# STM32L552xx register map
File version: 1.0
Registers are 32-bit, read-write, reset 0x0 unless marked. A register's access mark holds for its fields unless they carry their own. Offsets are from the block's base; [hi:lo] are bit positions; {n}, {i} and the like mark numbered series.

## SPI2 — Serial Peripheral Interface
Base 0x40003800
Same registers: SPI3 0x40003C00, SPI1 0x40013000, SPI2_S 0x50003800, SPI3_S 0x50003C00, SPI1_S 0x50013000
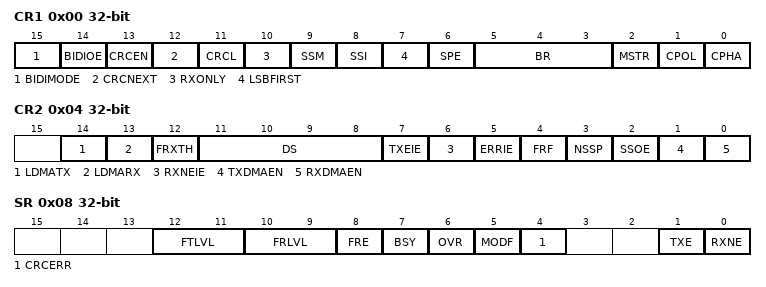
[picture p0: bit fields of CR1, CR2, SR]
0x00 CR1 — SPI Control register 1
  [15] BIDIMODE — Bidirectional data mode enable
  [14] BIDIOE — Output enable in bidirectional mode
  [13] CRCEN — Hardware CRC calculation enable
  [12] CRCNEXT — Transmit CRC next
  [11] CRCL — CRC Length
    0=CRC_8BIT (8-bit CRC length); 1=CRC_16BIT (16-bit CRC length)
  [10] RXONLY — Receive only
  [9] SSM — Software slave management
  [8] SSI — Internal slave select
  [7] LSBFIRST — Frame Format
    1=LSB_FIRST (Data is transmitted/received with the LSB first); 0=MSB_FIRST (Data is transmitted/received with the MSB first)
  [6] SPE — SPI Enable
  [5:3] BR — BR[2:0] bits (Baud Rate Control)
    0=DIV2 (BaudRate control equal to fPCLK/2); 1=DIV4 (BaudRate control equal to fPCLK/4); 2=DIV8 (BaudRate control equal to fPCLK/8); 3=DIV16 (BaudRate control equal to fPCLK/16); 4=DIV32 (BaudRate control equal to fPCLK/32); 5=DIV64 (BaudRate control equal to fPCLK/64); 6=DIV128 (BaudRate control equal to fPCLK/128); 7=DIV256 (BaudRate control equal to fPCLK/256)
  [2] MSTR — Master Selection
  [1] CPOL — Clock Polarity
    0=LOW (Clock to 0 when idle); 1=HIGH (Clock to 1 when idle)
  [0] CPHA — Clock Phase
    0=PHASE_1EDGE (First clock transition is the first data capture edge); 1=PHASE_2EDGE (Second clock transition is the first data capture edge)
0x04 CR2 — SPI Control register 2
  [14] LDMATX — Last DMA transfer for transmission
  [13] LDMARX — Last DMA transfer for reception
  [12] FRXTH — FIFO reception Threshold
    0=HALF (RXNE event is generated if FIFO level is greater than or equal to 1/2 (16-bit)); 1=QUARTER (RXNE event is generated if FIFO level is greater than or equal to 1/4 (8-bit))
  [11:8] DS — DS[3:0] Data Size
    {v}=DATAWIDTH_{v+1}BIT (Data length for SPI transfer: {v+1} bits) (v=3..15)
  [7] TXEIE — Tx buffer Empty Interrupt Enable
  [6] RXNEIE — RX buffer Not Empty Interrupt Enable
  [5] ERRIE — Error Interrupt Enable
  [4] FRF — Frame Format Enable
    0=MOTOROLA (Motorola mode. Used as default value); 1=TI (TI mode)
  [3] NSSP — NSS pulse management Enable
  [2] SSOE — SS Output Enable
  [1] TXDMAEN — Tx Buffer DMA Enable
  [0] RXDMAEN — Rx Buffer DMA Enable
0x08 SR — SPI Status register
  [12:11] FTLVL — FIFO Transmission Level
    0=EMPTY (FIFO transmission empty); 1=QUARTER_FULL (FIFO transmission 1/4); 2=HALF_FULL (FIFO transmission 1/2); 3=FULL (FIFO transmission full)
  [10:9] FRLVL — FIFO Reception Level
    0=EMPTY (FIFO reception empty); 1=QUARTER_FULL (FIFO reception 1/4); 2=HALF_FULL (FIFO reception 1/2); 3=FULL (FIFO reception full)
  [8] FRE — TI frame format error
  [7] BSY — Busy flag
  [6] OVR — Overrun flag
  [5] MODF — Mode fault
  [4] CRCERR — CRC Error flag
  [1] TXE — Transmit buffer Empty
  [0] RXNE — Receive buffer Not Empty
0x0C DR — SPI data register
  [15:0] DR — Data Register
0x10 CRCPR — SPI CRC polynomial register
  [15:0] CRCPOLY — CRC polynomial register
0x14 RXCRCR — SPI Rx CRC register
  [15:0] RXCRC
0x18 TXCRCR — SPI Tx CRC register
  [15:0] TXCRC

## CRS — Clock Recovery System
Base 0x40006000
Same registers: CRS_S 0x50006000
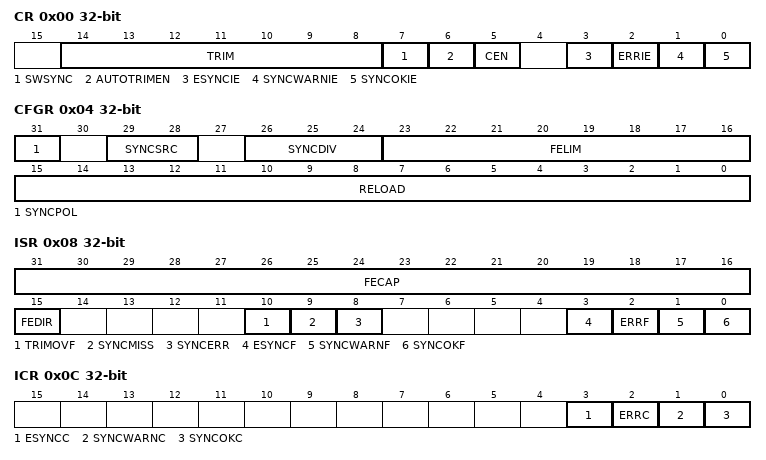
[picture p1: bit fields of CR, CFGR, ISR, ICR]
0x00 CR — CRS ccontrol register
  [14:8] TRIM — HSI48 oscillator smooth trimming
  [7] SWSYNC — Generate software SYNC event
  [6] AUTOTRIMEN — Automatic trimming enable
  [5] CEN — Frequency error counter enable
  [3] ESYNCIE — Expected SYNC interrupt enable
  [2] ERRIE — SYNC error or trimming error interrupt enable
  [1] SYNCWARNIE — SYNC warning interrupt enable
  [0] SYNCOKIE — SYNC event OK interrupt enable
0x04 CFGR — CRS configuration register
  [31] SYNCPOL — SYNC polarity selection
    0=RISING (Synchro Active on rising edge (default)); 1=FALLING (Synchro Active on falling edge)
  [29:28] SYNCSRC — SYNC signal source selection
    0=GPIO (Synchro Signal source GPIO); 1=LSE (Synchro Signal source LSE); 2=USB (Synchro Signal source USB SOF (default))
  [26:24] SYNCDIV — SYNC divider
    0=DIV_1 (Synchro Signal not divided (default)); 1=DIV_2 (Synchro Signal divided by 2); 2=DIV_4 (Synchro Signal divided by 4); 3=DIV_8 (Synchro Signal divided by 8); 4=DIV_16 (Synchro Signal divided by 16); 5=DIV_32 (Synchro Signal divided by 32); 6=DIV_64 (Synchro Signal divided by 64); 7=DIV_128 (Synchro Signal divided by 128)
  [23:16] FELIM — Frequency error limit
  [15:0] RELOAD — Counter reload value
0x08 ISR — CRS interrupt and status register
  [31:16] FECAP — Frequency error capture
  [15] FEDIR — Frequency error direction
    0=UP (Upcounting direction, the actual frequency is above the target); 1=DOWN (Downcounting direction, the actual frequency is below the target)
  [10] TRIMOVF — Trimming overflow or underflow
  [9] SYNCMISS — SYNC missed
  [8] SYNCERR — SYNC error
  [3] ESYNCF — Expected SYNC flag
  [2] ERRF — Error flag
  [1] SYNCWARNF — SYNC warning flag
  [0] SYNCOKF — SYNC event OK flag
0x0C ICR — CRS interrupt flag clear register
  [3] ESYNCC — Expected SYNC clear flag
  [2] ERRC — Error clear flag
  [1] SYNCWARNC — SYNC warning clear flag
  [0] SYNCOKC — SYNC event OK clear flag
